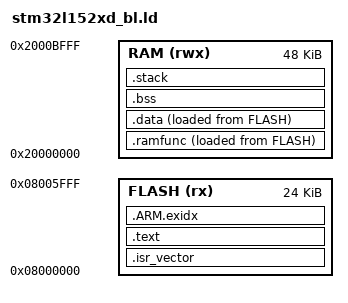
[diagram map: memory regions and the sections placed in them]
/*
 * Linker script for the 121GW SD-card bootloader (STM32L15xxD).
 *
 * Flash:  0x08000000, 24 KB (the application starts at 0x08006000).
 * RAM:    RAM code at 0x20000000 (as the original), then data, bss and a
 *         4 KB stack, matching the original's 0x1000-byte CSTACK.
 */
ENTRY(Reset_Handler)

MEMORY
{
    FLASH (rx)  : ORIGIN = 0x08000000, LENGTH = 24K
    RAM   (rwx) : ORIGIN = 0x20000000, LENGTH = 48K
}

STACK_SIZE = 0x1000;

SECTIONS
{
    .isr_vector :
    {
        KEEP(*(.isr_vector))
    } > FLASH

    .text :
    {
        . = ALIGN(4);
        *(.text*)
        *(.rodata*)
        . = ALIGN(4);
    } > FLASH

    .ARM.exidx :
    {
        *(.ARM.exidx*)
    } > FLASH

    .ramfunc :
    {
        . = ALIGN(4);
        _sramfunc = .;
        *(.ramfunc*)
        . = ALIGN(4);
        _eramfunc = .;
    } > RAM AT > FLASH
    _siramfunc = LOADADDR(.ramfunc);

    .data :
    {
        . = ALIGN(4);
        _sdata = .;
        *(.data*)
        . = ALIGN(4);
        _edata = .;
    } > RAM AT > FLASH
    _sidata = LOADADDR(.data);

    .bss (NOLOAD) :
    {
        . = ALIGN(4);
        _sbss = .;
        *(.bss*)
        *(COMMON)
        . = ALIGN(4);
        _ebss = .;
    } > RAM

    .stack (NOLOAD) :
    {
        . = ALIGN(8);
        . = . + STACK_SIZE;
        . = ALIGN(8);
        _estack = .;
    } > RAM
}
